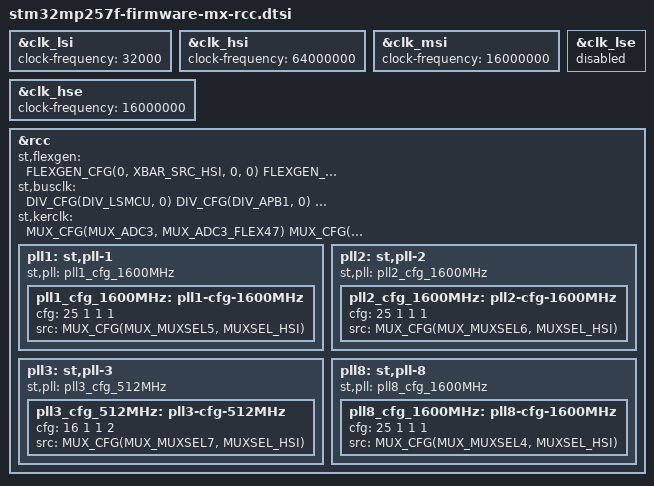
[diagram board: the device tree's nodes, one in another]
// SPDX-License-Identifier: (GPL-2.0-only OR BSD-3-Clause)
/*
 * Copyright (C) 2025, STMicroelectronics - All Rights Reserved
 * Author: STM32CubeMX code generation for STMicroelectronics.
 */

/* For more information on Device Tree configuration, please refer to
 * https://wiki.st.com/stm32mpu/wiki/Category:Device_tree_configuration
 */

&clk_lsi {
	clock-frequency = <32000>;

	/* USER CODE BEGIN clk_lsi */
	/* USER CODE END clk_lsi */
};
&clk_hsi {
	clock-frequency = <64000000>;

	/* USER CODE BEGIN clk_hsi */
	/* USER CODE END clk_hsi */
};
&clk_msi {
	clock-frequency = <16000000>;

	/* USER CODE BEGIN clk_msi */
	/* USER CODE END clk_msi */
};
&clk_lse {
	status = "disabled";

	/* USER CODE BEGIN clk_lse */
	/* USER CODE END clk_lse */
};
&clk_hse {
	clock-frequency = <16000000>;

	/* USER CODE BEGIN clk_hse */
	/* USER CODE END clk_hse */
};

&rcc {

	st,flexgen = <

		FLEXGEN_CFG(0, XBAR_SRC_HSI, 0, 0)
		FLEXGEN_CFG(1, XBAR_SRC_HSI, 0, 0)
		FLEXGEN_CFG(2, XBAR_SRC_HSI, 0, 0)
		FLEXGEN_CFG(3, XBAR_SRC_HSI, 0, 0)
		FLEXGEN_CFG(4, XBAR_SRC_HSI, 0, 0)
		FLEXGEN_CFG(5, XBAR_SRC_HSI, 0, 0)
		FLEXGEN_CFG(6, XBAR_SRC_HSI, 0, 0)
		FLEXGEN_CFG(10, XBAR_SRC_HSI_KER, 0, 0)
		FLEXGEN_CFG(12, XBAR_SRC_HSI_KER, 0, 0)
		FLEXGEN_CFG(13, XBAR_SRC_HSI_KER, 0, 0)
		FLEXGEN_CFG(15, XBAR_SRC_HSI_KER, 0, 0)
		FLEXGEN_CFG(20, XBAR_SRC_HSI_KER, 0, 0)
		FLEXGEN_CFG(26, XBAR_SRC_HSE_KER, 0, 12)
		FLEXGEN_CFG(27, XBAR_SRC_PLL8, 0, 5)
		FLEXGEN_CFG(28, XBAR_SRC_HSE_KER, 0, 59)
		FLEXGEN_CFG(29, XBAR_SRC_PLL8, 0, 4)
		FLEXGEN_CFG(30, XBAR_SRC_HSE_KER, 1, 39)
		FLEXGEN_CFG(31, XBAR_SRC_HSE_KER, 0, 59)
		FLEXGEN_CFG(33, XBAR_SRC_HSI_KER, 0, 0)
		FLEXGEN_CFG(34, XBAR_SRC_HSE_KER, 0, 63)
		FLEXGEN_CFG(37, XBAR_SRC_HSI_KER, 0, 0)
		FLEXGEN_CFG(43, XBAR_SRC_PLL8, 0, 24)
		FLEXGEN_CFG(44, XBAR_SRC_PLL8, 0, 7)
		FLEXGEN_CFG(45, XBAR_SRC_PLL8, 0, 3)
		FLEXGEN_CFG(47, XBAR_SRC_PLL8, 0, 12)
		FLEXGEN_CFG(51, XBAR_SRC_HSI_KER, 0, 0)
		FLEXGEN_CFG(54, XBAR_SRC_PLL8, 0, 12)
		FLEXGEN_CFG(56, XBAR_SRC_HSI_KER, 0, 0)
		FLEXGEN_CFG(57, XBAR_SRC_HSE_KER, 1, 33)
		FLEXGEN_CFG(58, XBAR_SRC_HSE_KER, 1, 33)
		FLEXGEN_CFG(59, XBAR_SRC_PLL8, 0, 2)
		FLEXGEN_CFG(60, XBAR_SRC_PLL8, 0, 31)
		FLEXGEN_CFG(63, XBAR_SRC_HSI_KER, 0, 0)
	>;

	st,busclk = <
		DIV_CFG(DIV_LSMCU, 0)
		DIV_CFG(DIV_APB1, 0)
		DIV_CFG(DIV_APB2, 0)
		DIV_CFG(DIV_APB3, 0)
		DIV_CFG(DIV_APB4, 0)
		DIV_CFG(DIV_APBDBG, 0)
	>;

	st,kerclk = <
		MUX_CFG(MUX_ADC3, MUX_ADC3_FLEX47)
		MUX_CFG(MUX_D3PER, MUX_D3PER_MSI)
		MUX_CFG(MUX_USB2PHY1, MUX_USB2PHY1_FLEX57)
		MUX_CFG(MUX_USB2PHY2, MUX_USB2PHY2_FLEX58)
		MUX_CFG(MUX_USB3PCIEPHY, MUX_USB3PCIEPHY_FLEX34)
		MUX_CFG(MUX_DSIBLANE, MUX_DSIBLANE_DSIPHY)
		MUX_CFG(MUX_DSIPHY, MUX_DSIPHY_FLEX28)

	>;

	pll1:st,pll-1 {
		st,pll = <&pll1_cfg_1600MHz>;

		pll1_cfg_1600MHz: pll1-cfg-1600MHz{
			cfg = <25 1 1 1>;
			src = <MUX_CFG(MUX_MUXSEL5, MUXSEL_HSI)>;
		};
		/* USER CODE BEGIN pll1 */
		/* USER CODE END pll1 */
	};

	pll2:st,pll-2 {
		st,pll = <&pll2_cfg_1600MHz>;

		pll2_cfg_1600MHz: pll2-cfg-1600MHz{
			cfg = <25 1 1 1>;
			src = <MUX_CFG(MUX_MUXSEL6, MUXSEL_HSI)>;
		};
		/* USER CODE BEGIN pll2 */
		/* USER CODE END pll2 */
	};

	pll3:st,pll-3 {
		st,pll = <&pll3_cfg_512MHz>;

		pll3_cfg_512MHz: pll3-cfg-512MHz{
			cfg = <16 1 1 2>;
			src = <MUX_CFG(MUX_MUXSEL7, MUXSEL_HSI)>;
		};
		/* USER CODE BEGIN pll3 */
		/* USER CODE END pll3 */
	};

	pll8:st,pll-8 {
		st,pll = <&pll8_cfg_1600MHz>;

		pll8_cfg_1600MHz: pll8-cfg-1600MHz{
			cfg = <25 1 1 1>;
			src = <MUX_CFG(MUX_MUXSEL4, MUXSEL_HSI)>;
		};
		/* USER CODE BEGIN pll8 */
		/* USER CODE END pll8 */
	};

	/* USER CODE BEGIN rcc */
	/* USER CODE END rcc */
};
